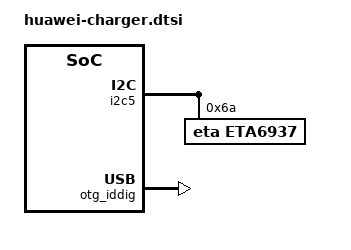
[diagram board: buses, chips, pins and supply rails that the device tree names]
&i2c5 {
	eta6937@6A {
		status = "okay";
		compatible = "eta,eta6937";
		reg = <0x6A>;

		/*ti,charging-disabled;*/
		ti,eta6937,enable-term;

		ti,eta6937,current-sensor-mohm = <56>;
		ti,eta6937,charge-voltage = <4400>;
		ti,eta6937,charge-current = <1100>;
		ti,eta6937,input-current-limit = <0>;/*iin-lim, 0 means no limit*/
		ti,eta6937,input-voltage-limit = <4500>;/*vindpm threshold*/
		ti,eta6937,vbatlow-volt = <3500>;
		ti,eta6937,term-current = <100>;
		ti,eta6937,safety-max-charge-current = <1550>;
		ti,eta6937,safety-max-charge-voltage = <4400>;
	};
};

&charger {
	ac_charger_current = <1050000>;
	ac_charger_input_current = <15000000>;
};

&bat_gm30 {
	batt_id_volt_by_adc;
};

&lk_charger{
	ac_charger_current = <1050000>;
	ac_charger_input_current = <1050000>;
};

&mt6370_pmu{
    charger {
	    status = "disabled";
    };
};

&otg_iddig {
	interrupt-parent = <&pio>;
	interrupts = <41 IRQ_TYPE_LEVEL_LOW 41 0>;
	status = "okay";
};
